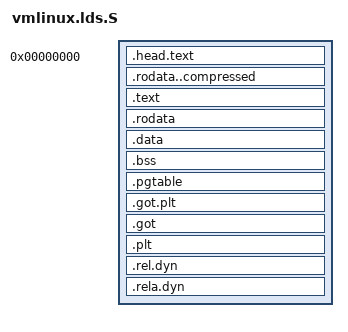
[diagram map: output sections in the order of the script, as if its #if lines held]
FASTVC-BENCH-CORPUS:linux-main-100k-v1-e0bd41dc-8e12-4f1b-978d-a3645ae59da0
/* SPDX-License-Identifier: GPL-2.0 */
#include <asm-generic/vmlinux.lds.h>

OUTPUT_FORMAT(CONFIG_OUTPUT_FORMAT)

#undef i386

#include <asm/cache.h>
#include <asm/page_types.h>

/* bench 667.1.0 1608e41fd475 */
/* bench 667.1.1 350132a03067 */
/* bench 667.1.2 fb512a564fe9 */
/* bench 667.1.3 0e17fa2ab34e */
/* bench 667.1.4 c988b3ff7020 */
/* bench 667.1.5 3fb420facd51 */
/* bench 667.1.6 947ebc8f1809 */
/* bench 667.1.7 7c23c9d870ab */
ENTRY(startup_64)
#else
OUTPUT_ARCH(i386)
ENTRY(startup_32)
#endif

SECTIONS
{
	/* Be careful parts of head_64.S assume startup_32 is at
	 * address 0.
	 */
	. = 0;
	.head.text : {
		_head = . ;
		HEAD_TEXT
		_ehead = . ;
	}
	.rodata..compressed : {
		*(.rodata..compressed)
	}
	.text :	{
		_text = .; 	/* Text */
		*(.text)
		*(.text.*)
		_etext = . ;
	}
	.rodata : {
		_rodata = . ;
		*(.rodata)	 /* read-only data */
		*(.rodata.*)
		_erodata = . ;
	}
	.data :	{
		_data = . ;
		*(.data)
		*(.data.*)
		*(.bss.efistub)
		_edata = . ;
	}
	. = ALIGN(L1_CACHE_BYTES);
	.bss : {
		_bss = . ;
		*(.bss)
		*(.bss.*)
		*(COMMON)
		. = ALIGN(8);	/* For convenience during zeroing */
		_ebss = .;
	}
#ifdef CONFIG_X86_64
       . = ALIGN(PAGE_SIZE);
       .pgtable : {
		_pgtable = . ;
		*(.pgtable)
		_epgtable = . ;
	}
#endif
	. = ALIGN(PAGE_SIZE);	/* keep ZO size page aligned */
	_end = .;

	STABS_DEBUG
	DWARF_DEBUG
	ELF_DETAILS

	DISCARDS
	/DISCARD/ : {
		*(.dynamic) *(.dynsym) *(.dynstr) *(.dynbss)
		*(.hash) *(.gnu.hash)
		*(.note.*)
	}

	.got.plt (INFO) : {
		*(.got.plt)
	}
	ASSERT(SIZEOF(.got.plt) == 0 ||
#ifdef CONFIG_X86_64
	       SIZEOF(.got.plt) == 0x18,
#else
	       SIZEOF(.got.plt) == 0xc,
#endif
	       "Unexpected GOT/PLT entries detected!")
/* bench 23013.2.0 39520c9477c7 */
/* bench 23013.2.1 12f2acc9d983 */
/* bench 23013.2.2 71a6a0fb9961 */
/* bench 23013.2.3 e0fc9e87bc92 */
/* bench 23013.2.4 01a2e9481339 */
	 * explicitly check instead of blindly discarding.
	 */
	.got : {
		*(.got)
	}
	ASSERT(SIZEOF(.got) == 0, "Unexpected GOT entries detected!")

	.plt : {
		*(.plt) *(.plt.*)
	}
	ASSERT(SIZEOF(.plt) == 0, "Unexpected run-time procedure linkages detected!")

	.rel.dyn : {
		*(.rel.*) *(.rel_*)
	}
	ASSERT(SIZEOF(.rel.dyn) == 0, "Unexpected run-time relocations (.rel) detected!")

	.rela.dyn : {
		*(.rela.*) *(.rela_*)
	}
	ASSERT(SIZEOF(.rela.dyn) == 0, "Unexpected run-time relocations (.rela) detected!")
}
